VERSION "0.81"

NS_ :

BS_:

BU_:

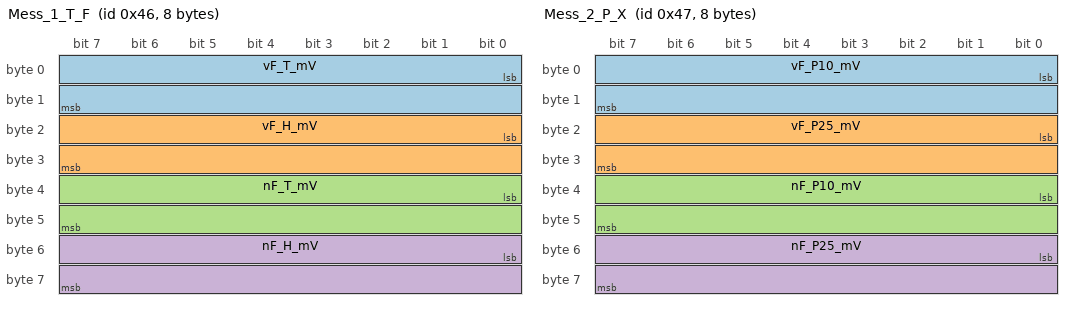
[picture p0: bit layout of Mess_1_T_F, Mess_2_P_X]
BO_ 70 Mess_1_T_F: 8 SM_1
 SG_ vF_T_mV : 0|16@1- (1,0) [-1000|1000] "mV"  SM_1
 SG_ vF_H_mV : 16|16@1- (1,0) [-1000|1000] "mV"  SM_1
 SG_ nF_T_mV : 32|16@1- (1,0) [-1000|1000] "mV"  SM_1
 SG_ nF_H_mV : 48|16@1- (1,0) [-1000|1000] "mV"  SM_1

BO_ 71 Mess_2_P_X: 8 SM_1
 SG_ vF_P10_mV : 0|16@1- (1,0) [-1000|1000] "mV"  SM_1
 SG_ vF_P25_mV : 16|16@1- (1,0) [-1000|1000] "mV"  SM_1
 SG_ nF_P10_mV : 32|16@1- (1,0) [-1000|1000] "mV"  SM_1
 SG_ nF_P25_mV : 48|16@1- (1,0) [-1000|1000] "mV"  SM_1

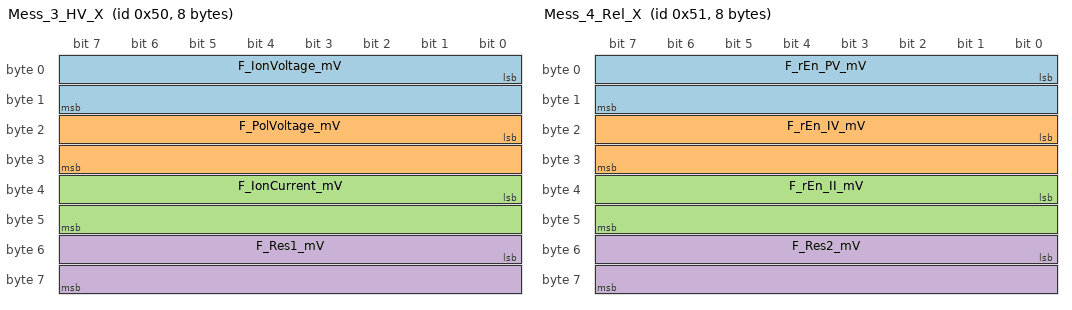
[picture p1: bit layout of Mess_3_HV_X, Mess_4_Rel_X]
BO_ 80 Mess_3_HV_X: 8 SM_2
 SG_ F_IonVoltage_mV : 0|16@1- (1,0) [-1000|1000] "mV"  SM_2
 SG_ F_PolVoltage_mV : 16|16@1- (1,0) [-1000|1000] "mV"  SM_2
 SG_ F_IonCurrent_mV : 32|16@1- (1,0) [-1000|1000] "mV"  SM_2
 SG_ F_Res1_mV : 48|16@1- (1,0) [-1000|1000] "mV"  SM_2

BO_ 81 Mess_4_Rel_X: 8 SM_2
 SG_ F_rEn_PV_mV : 0|16@1- (1,0) [-1000|1000] "mV"  SM_2
 SG_ F_rEn_IV_mV : 16|16@1- (1,0) [-1000|1000] "mV"  SM_2
 SG_ F_rEn_II_mV : 32|16@1- (1,0) [-1000|1000] "mV"  SM_2
 SG_ F_Res2_mV : 48|16@1- (1,0)  [-1000|1000] "mV"  SM_2
